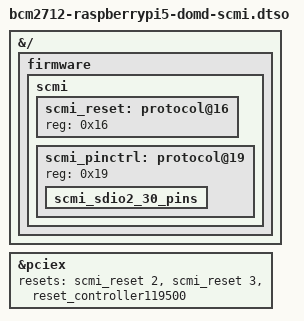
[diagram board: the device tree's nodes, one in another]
// SPDX-License-Identifier: GPL-2.0
/dts-v1/;
/plugin/;

&{/} {
	firmware {
		scmi {
			#address-cells = <1>;
			#size-cells = <0>;

			scmi_reset: protocol@16 {
				reg = <0x16>;
				#reset-cells = <0x1>;
			};

			scmi_pinctrl: protocol@19 {
				reg = <0x19>;
				#pinctrl-cells = <0>;

				scmi_sdio2_30_pins: scmi_sdio2_30_pins {
				};
			};
		};
	};
};

&pciex {
	resets = <&scmi_reset 2>, <&scmi_reset 3>, <&reset_controller119500>;
};
